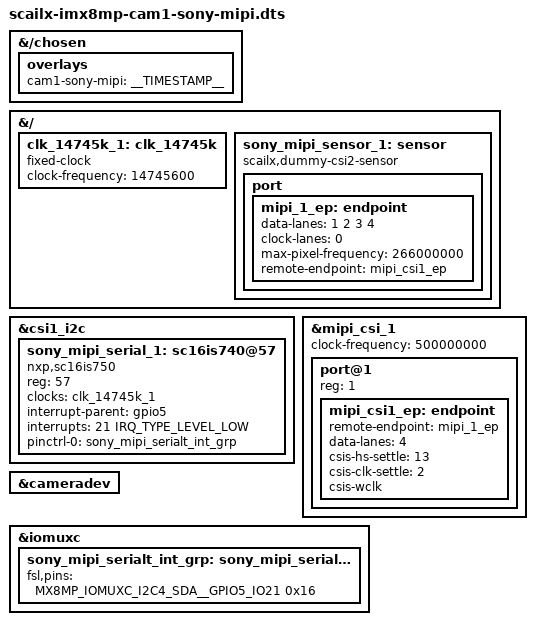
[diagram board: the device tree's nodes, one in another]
// SPDX-License-Identifier: (GPL-2.0 OR MIT)
/*
 * Copyright (C) 2024 VideologyInc
 *
 */

/dts-v1/;
/plugin/;

#include "imx8mp-pinfunc.h"
#include <dt-bindings/clock/imx8mp-clock.h>
#include <dt-bindings/interrupt-controller/arm-gic.h>

&{/chosen} {
	overlays {
		cam1-sony-mipi = __TIMESTAMP__;
	};
};

&{/} {
	clk_14745k_1: clk_14745k {
		compatible = "fixed-clock";
		#clock-cells = <0>;
		clock-frequency = <14745600>;
	};

	sony_mipi_sensor_1: sensor {
		compatible = "scailx,dummy-csi2-sensor";
		status = "okay";

		port {
			mipi_1_ep: endpoint {
				data-lanes = <1 2 3 4>;
				clock-lanes = <0>;
				max-pixel-frequency = /bits/ 64 <266000000>;
				remote-endpoint = <&mipi_csi1_ep>;
			};
		};
	};
};

&csi1_i2c {
	#address-cells = <1>;
	#size-cells = <0>;
	sony_mipi_serial_1: sc16is740@57 {
		compatible = "nxp,sc16is750", "nxp,sc16is740";
		reg = <57>;
		clocks = <&clk_14745k_1>;
		interrupt-parent = <&gpio5>;
		interrupts = <21 IRQ_TYPE_LEVEL_LOW>;
		pinctrl-0 = <&sony_mipi_serialt_int_grp>;
		pinctrl-names = "default";
		// gpio-controller;
		// #gpio-cells = <2>;
	};
};

&mipi_csi_1 {
	#address-cells = <1>;
	#size-cells = <0>;
	clock-frequency = <500000000>;
	status = "okay";

	port@1 {
		reg = <1>;
		mipi_csi1_ep: endpoint {
			remote-endpoint = <&mipi_1_ep>;
			data-lanes = <4>;
			csis-hs-settle = <13>;
			csis-clk-settle = <2>;
			csis-wclk;
		};
	};
};

&cameradev {
	status = "okay";
};

&iomuxc {
	sony_mipi_serialt_int_grp: sony_mipi_serialt_int {
		fsl,pins = <
			MX8MP_IOMUXC_I2C4_SDA__GPIO5_IO21   0x16
		>;
	};
};
